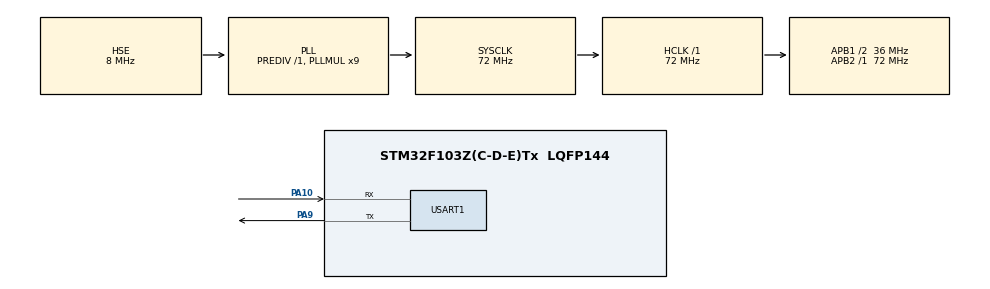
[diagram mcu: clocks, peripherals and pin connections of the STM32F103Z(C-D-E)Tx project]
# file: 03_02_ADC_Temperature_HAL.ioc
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ADC1.Channel-1\#ChannelRegularConversion=ADC_CHANNEL_TEMPSENSOR
ADC1.ContinuousConvMode=ENABLE
ADC1.NbrOfConversionFlag=1
ADC1.Rank-1\#ChannelRegularConversion=1
ADC1.SamplingTime-1\#ChannelRegularConversion=ADC_SAMPLETIME_239CYCLES_5
ADC1.master=1
Dma.Request0=USART1_RX
Dma.USART1_RX.0.Direction=DMA_PERIPH_TO_MEMORY
Dma.USART1_RX.0.Instance=DMA1_Channel5
Dma.USART1_RX.0.MemDataAlignment=DMA_MDATAALIGN_BYTE
Dma.USART1_RX.0.MemInc=DMA_MINC_ENABLE
Dma.USART1_RX.0.Mode=DMA_CIRCULAR
Dma.USART1_RX.0.PeriphDataAlignment=DMA_PDATAALIGN_BYTE
Dma.USART1_RX.0.PeriphInc=DMA_PINC_DISABLE
Dma.USART1_RX.0.Priority=DMA_PRIORITY_LOW
Mcu.Family=STM32F1
Mcu.Name=STM32F103Z(C-D-E)Tx
Mcu.Package=LQFP144
NVIC.DMA1_Channel5_IRQn=true\:5\:0\:true\:false\:true\:false\:true\:true
NVIC.PriorityGroup=NVIC_PRIORITYGROUP_4
NVIC.USART1_IRQn=true\:5\:0\:true\:false\:true\:true\:true\:true
OSC_IN.Mode=HSE-External-Oscillator
OSC_IN.Signal=RCC_OSC_IN
OSC_OUT.Mode=HSE-External-Oscillator
OSC_OUT.Signal=RCC_OSC_OUT
PA10.Mode=Asynchronous
PA10.Signal=USART1_RX
PA13.Mode=Serial_Wire
PA13.Signal=SYS_JTMS-SWDIO
PA14.Mode=Serial_Wire
PA14.Signal=SYS_JTCK-SWCLK
PA9.Mode=Asynchronous
PA9.Signal=USART1_TX
PC14-OSC32_IN.Mode=LSE-External-Oscillator
PC14-OSC32_IN.Signal=RCC_OSC32_IN
PC15-OSC32_OUT.Mode=LSE-External-Oscillator
PC15-OSC32_OUT.Signal=RCC_OSC32_OUT
ProjectManager.HeapSize=0x200
ProjectManager.StackSize=0x400
ProjectManager.TargetToolchain=MDK-ARM V5.32
RCC.ADCPresc=RCC_ADCPCLK2_DIV6
RCC.AHBFreq_Value=72000000
RCC.APB1CLKDivider=RCC_HCLK_DIV2
RCC.APB1Freq_Value=36000000
RCC.APB1TimFreq_Value=72000000
RCC.APB2Freq_Value=72000000
RCC.APB2TimFreq_Value=72000000
RCC.HCLKFreq_Value=72000000
RCC.PLLMUL=RCC_PLL_MUL9
RCC.PLLSourceVirtual=RCC_PLLSOURCE_HSE
RCC.SYSCLKFreq_VALUE=72000000
RCC.SYSCLKSource=RCC_SYSCLKSOURCE_PLLCLK
RCC.USBFreq_Value=72000000
USART1.VirtualMode=VM_ASYNC
VP_ADC1_TempSens_Input.Mode=IN-TempSens
board=custom

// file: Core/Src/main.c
/* USER CODE BEGIN Header */
/**
  ******************************************************************************
  * @file           : main.c
  * @brief          : Main program body
  ******************************************************************************
  * @attention
  *
  * Copyright (c) 2025 STMicroelectronics.
  * All rights reserved.
  *
  * This software is licensed under terms that can be found in the LICENSE file
  * in the root directory of this software component.
  * If no LICENSE file comes with this software, it is provided AS-IS.
  *
  ******************************************************************************
  */
/* USER CODE END Header */
#include "main.h"
#include "adc.h"
#include "dma.h"
#include "usart.h"
#include "gpio.h"

void SystemClock_Config(void);

int main(void)
{

  /* MCU Configuration--------------------------------------------------------*/

  /* Reset of all peripherals, Initializes the Flash interface and the Systick. */
  HAL_Init();

  /* Configure the system clock */
  SystemClock_Config();

  /* Initialize all configured peripherals */
  MX_GPIO_Init();
  MX_DMA_Init();
  MX_USART1_UART_Init();
  MX_ADC1_Init();
  /* USER CODE BEGIN 2 */

  printf("ADC Temperature Channel HAL Test\n");

  // 启动 ADC 校准， 该函数校准完成后调用结束
  HAL_ADCEx_Calibration_Start(&hadc1);
  // 启动 ADC1
  HAL_ADC_Start(&hadc1);

  // 等待第一次转换完成
  while (__HAL_ADC_GET_FLAG(&hadc1, ADC_FLAG_EOC) == RESET)
    ;

  double Vol = 0; // 电压值
  double Temp = 0; // 温度值

  double V25 = 1.43;
  double Avg_Slope = 0.0043;

  /* USER CODE END 2 */

  /* Infinite loop */
  while (1)
  {

    /* USER CODE BEGIN 3 */
    Vol = HAL_ADC_GetValue(&hadc1) / 4095.0 * 3.3;
    Temp = (V25 - Vol) / Avg_Slope + 25;
    printf("ADC Value: %d ,Vol: %.2lf V,Temp: %.2lf C\n", HAL_ADC_GetValue(&hadc1),Vol,Temp);
    HAL_Delay(1000);

  }
  /* USER CODE END 3 */
}

void SystemClock_Config(void)
{
  RCC_OscInitTypeDef RCC_OscInitStruct = {0};
  RCC_ClkInitTypeDef RCC_ClkInitStruct = {0};
  RCC_PeriphCLKInitTypeDef PeriphClkInit = {0};

  /** Initializes the RCC Oscillators according to the specified parameters
  * in the RCC_OscInitTypeDef structure.
  */
  RCC_OscInitStruct.OscillatorType = RCC_OSCILLATORTYPE_HSE;
  RCC_OscInitStruct.HSEState = RCC_HSE_ON;
  RCC_OscInitStruct.HSEPredivValue = RCC_HSE_PREDIV_DIV1;
  RCC_OscInitStruct.HSIState = RCC_HSI_ON;
  RCC_OscInitStruct.PLL.PLLState = RCC_PLL_ON;
  RCC_OscInitStruct.PLL.PLLSource = RCC_PLLSOURCE_HSE;
  RCC_OscInitStruct.PLL.PLLMUL = RCC_PLL_MUL9;
  if (HAL_RCC_OscConfig(&RCC_OscInitStruct) != HAL_OK)
  {
    Error_Handler();
  }

  /** Initializes the CPU, AHB and APB buses clocks
  */
  RCC_ClkInitStruct.ClockType = RCC_CLOCKTYPE_HCLK|RCC_CLOCKTYPE_SYSCLK
                              |RCC_CLOCKTYPE_PCLK1|RCC_CLOCKTYPE_PCLK2;
  RCC_ClkInitStruct.SYSCLKSource = RCC_SYSCLKSOURCE_PLLCLK;
  RCC_ClkInitStruct.AHBCLKDivider = RCC_SYSCLK_DIV1;
  RCC_ClkInitStruct.APB1CLKDivider = RCC_HCLK_DIV2;
  RCC_ClkInitStruct.APB2CLKDivider = RCC_HCLK_DIV1;

  if (HAL_RCC_ClockConfig(&RCC_ClkInitStruct, FLASH_LATENCY_2) != HAL_OK)
  {
    Error_Handler();
  }
  PeriphClkInit.PeriphClockSelection = RCC_PERIPHCLK_ADC;
  PeriphClkInit.AdcClockSelection = RCC_ADCPCLK2_DIV6;
  if (HAL_RCCEx_PeriphCLKConfig(&PeriphClkInit) != HAL_OK)
  {
    Error_Handler();
  }
}

void Error_Handler(void)
{
  __disable_irq();
  while (1)
  {
  }
}
